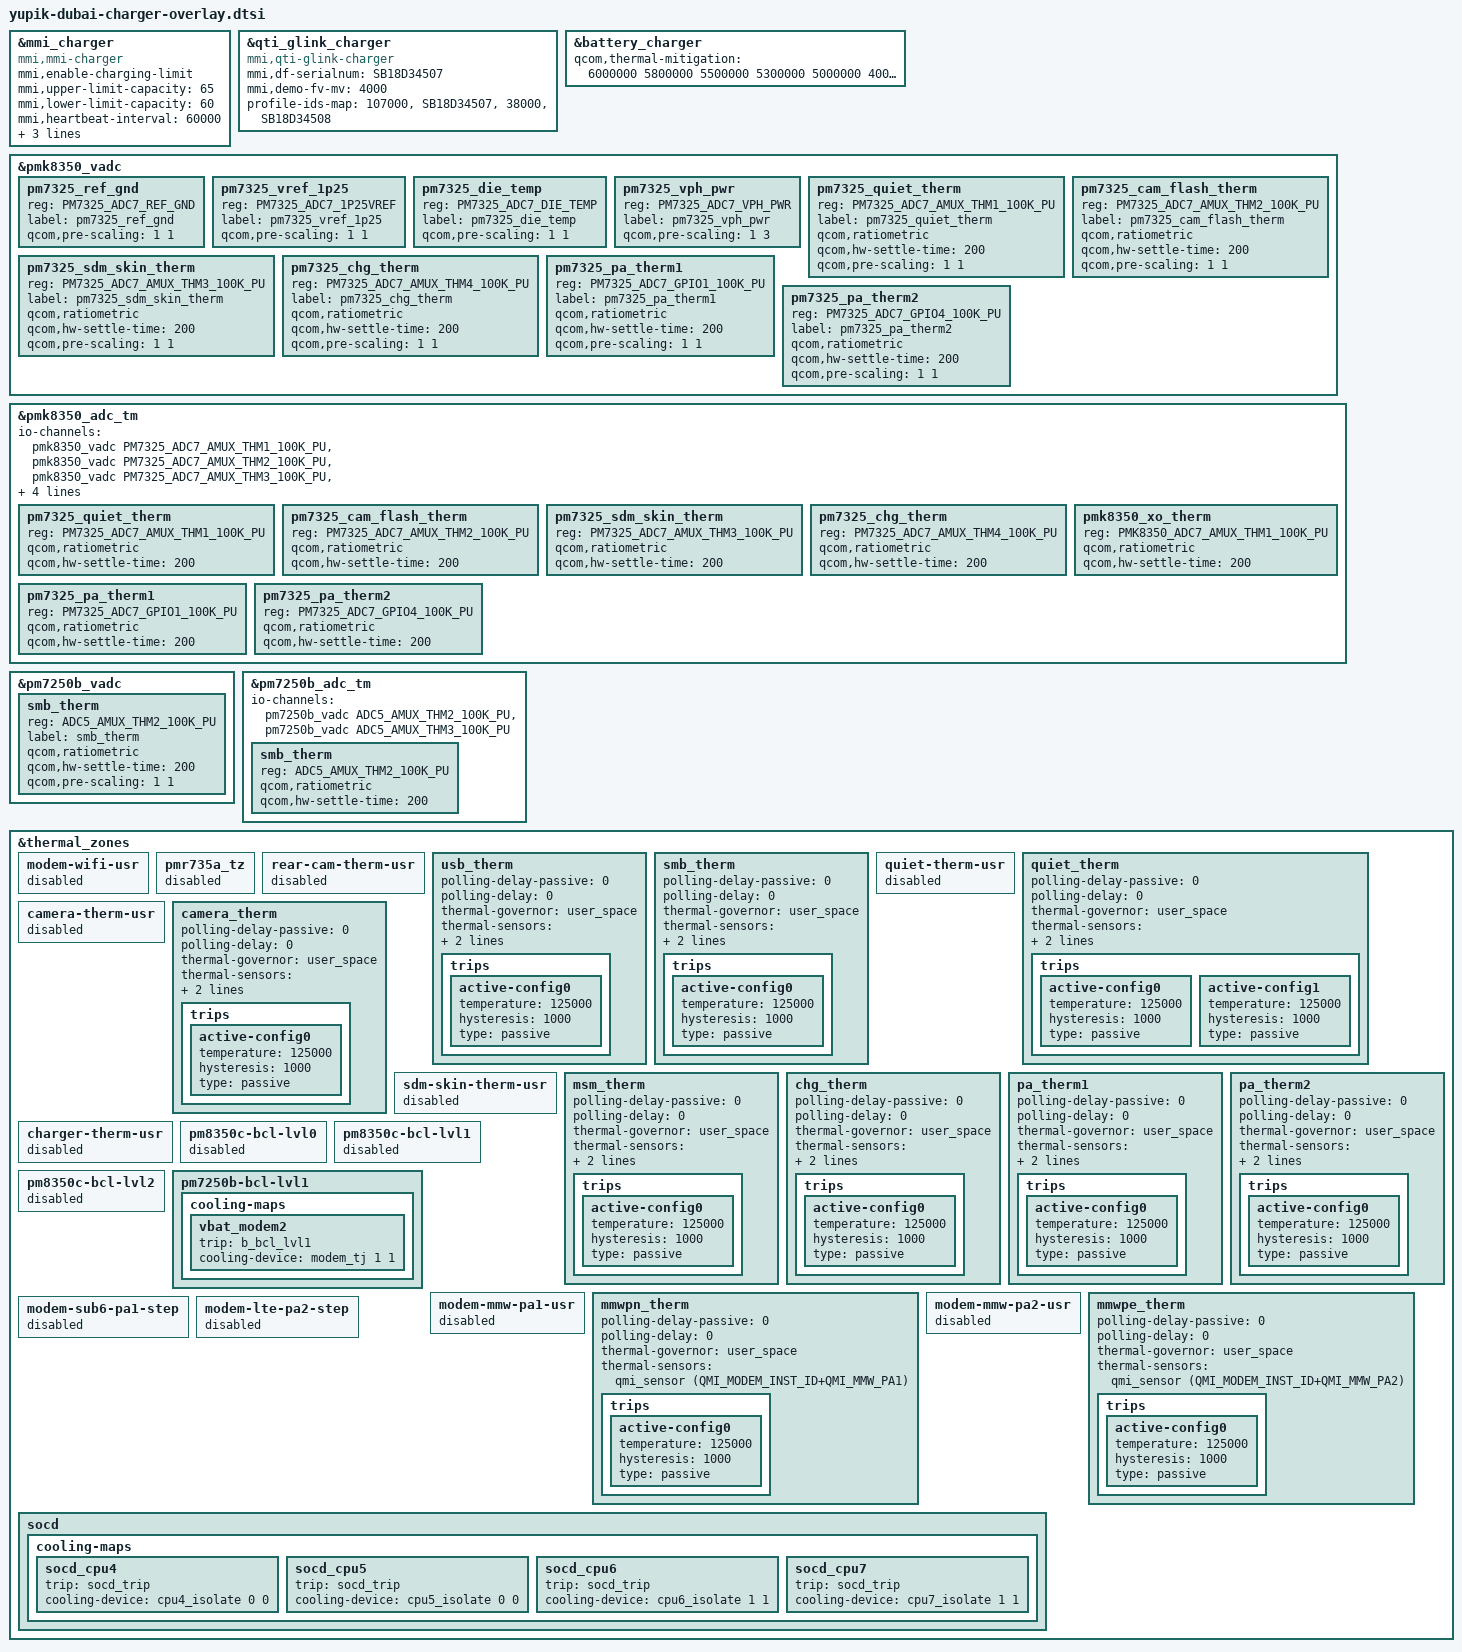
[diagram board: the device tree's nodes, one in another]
#include "moto_therm_sys_temp.dtsi"

&mmi_charger {
compatible = "mmi,mmi-charger";
	mmi,enable-charging-limit;
	mmi,upper-limit-capacity = <65>;
	mmi,lower-limit-capacity = <60>;
	mmi,heartbeat-interval = <60000>;
	mmi,dcp-power-max = <10000>;
	mmi,hvdcp-power-max = <20000>;
	mmi,pd-power-max = <30000>;
};

&qti_glink_charger {
	compatible = "mmi,qti-glink-charger";
	mmi,df-serialnum = "SB18D34507";
	mmi,demo-fv-mv = <4000>;
	profile-ids-map = "107000", "SB18D34507", "38000", "SB18D34508";
};

&battery_charger {
	qcom,thermal-mitigation = <6000000 5800000 5500000 5300000 5000000 4000000 3000000 1500000 1000000 500000>;
};

&pmk8350_vadc {
	/delete-node/ pm8350_ref_gnd;
	/delete-node/ pm8350_vref_1p25;
	/delete-node/ pm8350_die_temp;
	/delete-node/ pm8350_vph_pwr;

	/delete-node/ pm8350b_ref_gnd;
	/delete-node/ pm8350b_vref_1p25;
	/delete-node/ pm8350b_die_temp;
	/delete-node/ pm8350b_vph_pwr;
	/delete-node/ pm8350b_vbat_sns;

	/delete-node/ pmr735b_ref_gnd;
	/delete-node/ pmr735b_vref_1p25;
	/delete-node/ pmr735b_die_temp;

	/* PM7325 Channel nodes */
	pm7325_ref_gnd {
		reg = <PM7325_ADC7_REF_GND>;
		label = "pm7325_ref_gnd";
		qcom,pre-scaling = <1 1>;
	};

	pm7325_vref_1p25 {
		reg = <PM7325_ADC7_1P25VREF>;
		label = "pm7325_vref_1p25";
		qcom,pre-scaling = <1 1>;
	};

	pm7325_die_temp {
		reg = <PM7325_ADC7_DIE_TEMP>;
		label = "pm7325_die_temp";
		qcom,pre-scaling = <1 1>;
	};

	pm7325_vph_pwr {
		reg = <PM7325_ADC7_VPH_PWR>;
		label = "pm7325_vph_pwr";
		qcom,pre-scaling = <1 3>;
	};

	pm7325_quiet_therm {
		reg = <PM7325_ADC7_AMUX_THM1_100K_PU>;
		label = "pm7325_quiet_therm";
		qcom,ratiometric;
		qcom,hw-settle-time = <200>;
		qcom,pre-scaling = <1 1>;
	};

	pm7325_cam_flash_therm {
		reg = <PM7325_ADC7_AMUX_THM2_100K_PU>;
		label = "pm7325_cam_flash_therm";
		qcom,ratiometric;
		qcom,hw-settle-time = <200>;
		qcom,pre-scaling = <1 1>;
	};

	pm7325_sdm_skin_therm {
		reg = <PM7325_ADC7_AMUX_THM3_100K_PU>;
		label = "pm7325_sdm_skin_therm";
		qcom,ratiometric;
		qcom,hw-settle-time = <200>;
		qcom,pre-scaling = <1 1>;
	};

	pm7325_chg_therm {
		reg = <PM7325_ADC7_AMUX_THM4_100K_PU>;
		label = "pm7325_chg_therm";
		qcom,ratiometric;
		qcom,hw-settle-time = <200>;
		qcom,pre-scaling = <1 1>;
	};

	/delete-node/ pm7325_wide_rfc_therm;

	pm7325_pa_therm1 {
		reg = <PM7325_ADC7_GPIO1_100K_PU>;
		label = "pm7325_pa_therm1";
		qcom,ratiometric;
		qcom,hw-settle-time = <200>;
		qcom,pre-scaling = <1 1>;
	};

	pm7325_pa_therm2 {
		reg = <PM7325_ADC7_GPIO4_100K_PU>;
		label = "pm7325_pa_therm2";
		qcom,ratiometric;
		qcom,hw-settle-time = <200>;
		qcom,pre-scaling = <1 1>;
	};
};

&pmk8350_adc_tm {
	/delete-property/ io-channels;
	io-channels = <&pmk8350_vadc PM7325_ADC7_AMUX_THM1_100K_PU>,
			<&pmk8350_vadc PM7325_ADC7_AMUX_THM2_100K_PU>,
			<&pmk8350_vadc PM7325_ADC7_AMUX_THM3_100K_PU>,
			<&pmk8350_vadc PM7325_ADC7_AMUX_THM4_100K_PU>,
			<&pmk8350_vadc PM7325_ADC7_GPIO1_100K_PU>,
			<&pmk8350_vadc PM7325_ADC7_GPIO4_100K_PU>,
			<&pmk8350_vadc PMK8350_ADC7_AMUX_THM1_100K_PU>;

	pm7325_quiet_therm {
		reg = <PM7325_ADC7_AMUX_THM1_100K_PU>;
		qcom,ratiometric;
		qcom,hw-settle-time = <200>;
	};

	pm7325_cam_flash_therm {
		reg = <PM7325_ADC7_AMUX_THM2_100K_PU>;
		qcom,ratiometric;
		qcom,hw-settle-time = <200>;
	};

	pm7325_sdm_skin_therm {
		reg = <PM7325_ADC7_AMUX_THM3_100K_PU>;
		qcom,ratiometric;
		qcom,hw-settle-time = <200>;
	};

	pm7325_chg_therm {
		reg = <PM7325_ADC7_AMUX_THM4_100K_PU>;
		qcom,ratiometric;
		qcom,hw-settle-time = <200>;
	};

	pmk8350_xo_therm {
		reg = <PMK8350_ADC7_AMUX_THM1_100K_PU>;
		qcom,ratiometric;
		qcom,hw-settle-time = <200>;
	};

	/delete-node/ pm7325_wide_rfc_therm ;

	pm7325_pa_therm1 {
		reg = <PM7325_ADC7_GPIO1_100K_PU>;
		qcom,ratiometric;
		qcom,hw-settle-time = <200>;
	};

	pm7325_pa_therm2 {
		reg = <PM7325_ADC7_GPIO4_100K_PU>;
		qcom,ratiometric;
		qcom,hw-settle-time = <200>;
	};
};

&pm7250b_vadc {
	smb_therm {
		reg = <ADC5_AMUX_THM2_100K_PU>;
		label = "smb_therm";
		qcom,ratiometric;
		qcom,hw-settle-time = <200>;
		qcom,pre-scaling = <1 1>;
	};
};

&pm7250b_adc_tm {
	/delete-property/ io-channels;
	io-channels = 	<&pm7250b_vadc ADC5_AMUX_THM2_100K_PU>,
			<&pm7250b_vadc ADC5_AMUX_THM3_100K_PU>;


	smb_therm {
		reg = <ADC5_AMUX_THM2_100K_PU>;
		qcom,ratiometric;
		qcom,hw-settle-time = <200>;
	};
};

&thermal_zones {
	modem-wifi-usr {
		status = "disabled";
	};
	pmr735a_tz {
		status = "disabled";
	};
	rear-cam-therm-usr {
		status = "disabled";
	};
	//pm7250b thermal

	/delete-node/ conn-therm-usr;
        usb_therm {
                polling-delay-passive = <0>;
                polling-delay = <0>;
                thermal-governor = "user_space";
                thermal-sensors = <&pm7250b_adc_tm ADC5_AMUX_THM3_100K_PU>;
                wake-capable-sensor;
                trips {
                        active-config0 {
                                temperature = <125000>;
                                hysteresis = <1000>;
                                type = "passive";
                        };
                };
        };

	smb_therm {
                polling-delay-passive = <0>;
                polling-delay = <0>;
                thermal-governor = "user_space";
                thermal-sensors = <&pm7250b_adc_tm ADC5_AMUX_THM2_100K_PU>;
                wake-capable-sensor;
                trips {
                        active-config0 {
                                temperature = <125000>;
                                hysteresis = <1000>;
                                type = "passive";
                        };
                };
        };

	//pm7325 thermal
	quiet-therm-usr {
		status = "disabled";
	};
	quiet_therm {
		polling-delay-passive = <0>;
		polling-delay = <0>;
		thermal-governor = "user_space";
		thermal-sensors = <&pmk8350_adc_tm PM7325_ADC7_AMUX_THM1_100K_PU>;
		wake-capable-sensor;
		trips {
			active-config0 {
				temperature = <125000>;
				hysteresis = <1000>;
				type = "passive";
			};

			active-config1 {
				temperature = <125000>;
				hysteresis = <1000>;
				type = "passive";
			};
		};
	};

	camera-therm-usr {
		status = "disabled";
	};
	camera_therm {
		polling-delay-passive = <0>;
		polling-delay = <0>;
		thermal-governor = "user_space";
		thermal-sensors = <&pmk8350_adc_tm PM7325_ADC7_AMUX_THM2_100K_PU>;
		wake-capable-sensor;
		trips {
			active-config0 {
				temperature = <125000>;
				hysteresis = <1000>;
				type = "passive";
			};
		};
	};

	sdm-skin-therm-usr {
		status = "disabled";
	};
	msm_therm {
		polling-delay-passive = <0>;
		polling-delay = <0>;
		thermal-governor = "user_space";
		thermal-sensors = <&pmk8350_adc_tm PM7325_ADC7_AMUX_THM3_100K_PU>;
		wake-capable-sensor;
		trips {
			active-config0 {
				temperature = <125000>;
				hysteresis = <1000>;
				type = "passive";
			};
		};
	};

	chg_therm {
                polling-delay-passive = <0>;
                polling-delay = <0>;
                thermal-governor = "user_space";
                thermal-sensors = <&pmk8350_adc_tm PM7325_ADC7_AMUX_THM4_100K_PU>;
                wake-capable-sensor;
                trips {
                        active-config0 {
                                temperature = <125000>;
                                hysteresis = <1000>;
                                type = "passive";
                        };
                };
        };

	pa_therm1 {
		polling-delay-passive = <0>;
		polling-delay = <0>;
		thermal-governor = "user_space";
		thermal-sensors = <&pmk8350_adc_tm PM7325_ADC7_GPIO1_100K_PU>;
		wake-capable-sensor;
		trips {
			active-config0 {
				temperature = <125000>;
				hysteresis = <1000>;
				type = "passive";
			};
		};
	};
	pa_therm2 {
		polling-delay-passive = <0>;
		polling-delay = <0>;
		thermal-governor = "user_space";
		thermal-sensors = <&pmk8350_adc_tm PM7325_ADC7_GPIO4_100K_PU>;
		wake-capable-sensor;
		trips {
			active-config0 {
				temperature = <125000>;
				hysteresis = <1000>;
				type = "passive";
			};
		};
	};

	charger-therm-usr {
		status = "disabled";
	};
	pm8350c-bcl-lvl0 {
		status = "disabled";
	};
	pm8350c-bcl-lvl1 {
		status = "disabled";
	};
	pm8350c-bcl-lvl2 {
		status = "disabled";
	};

	pm7250b-bcl-lvl1 {
		cooling-maps {
			vbat_modem2 {
				trip = <&b_bcl_lvl1>;
				cooling-device = <&modem_tj 1 1>;
			};
		};
	};

	modem-mmw-pa1-usr {
		status = "disabled";
	};
	mmwpn_therm {
		polling-delay-passive = <0>;
		polling-delay = <0>;
		thermal-governor = "user_space";
		thermal-sensors = <&qmi_sensor
				(QMI_MODEM_INST_ID+QMI_MMW_PA1)>;
		trips {
			active-config0 {
				temperature = <125000>;
				hysteresis = <1000>;
				type = "passive";
			};
		};
	};

	modem-mmw-pa2-usr {
		status = "disabled";
	};
	mmwpe_therm {
		polling-delay-passive = <0>;
		polling-delay = <0>;
		thermal-governor = "user_space";
		thermal-sensors = <&qmi_sensor
				(QMI_MODEM_INST_ID+QMI_MMW_PA2)>;
		trips {
			active-config0 {
				temperature = <125000>;
				hysteresis = <1000>;
				type = "passive";
			};
		};
	};
	modem-sub6-pa1-step {
		status = "disabled";
	};
	modem-lte-pa2-step {
		status = "disabled";
	};

	socd {
                cooling-maps {
		       socd_cpu4 {
                                trip = <&socd_trip>;
                                cooling-device = <&cpu4_isolate 0 0>;
                       };
                       socd_cpu5 {
                                trip = <&socd_trip>;
                                cooling-device = <&cpu5_isolate 0 0>;
                       };
                       socd_cpu6 {
                                trip = <&socd_trip>;
                                cooling-device = <&cpu6_isolate 1 1>;
                       };
                       socd_cpu7 {
                                trip = <&socd_trip>;
                                cooling-device = <&cpu7_isolate 1 1>;
                       };
                };
        };
};
/*
&battery_charger {
	no-conn-therm;
};*/
